# LPC111x_LPC11Cxx register map
File version: 6
CPU: CM0 r0p0, little endian, no MPU, no FPU, 0x2 interrupt priority bits, 0x0 interrupts
Registers are 32-bit, read-write, reset 0x0 unless marked. A register's access mark holds for its fields unless they carry their own. Offsets are from the block's base; [hi:lo] are bit positions; 'fields as' and 'values as' point back to an identical list.

## IOCON — Product name title=UM10398 Chapter title=LPC1100XL series: I/O configuration (IOCONFIG) Modification date=2/22/2012 Major revision=8 Minor revision=not available
Base 0x40044000
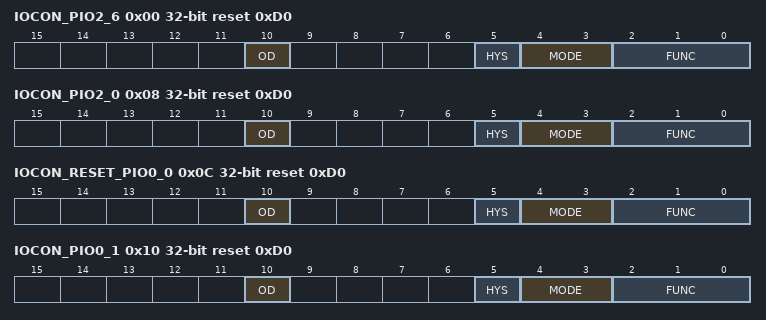
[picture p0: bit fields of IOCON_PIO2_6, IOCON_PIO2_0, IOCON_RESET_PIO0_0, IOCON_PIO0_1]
0x00 IOCON_PIO2_6 reset 0xD0 — I/O configuration for pin PIO2_6/ CT32B0_MAT1
  [10] OD — Selects pseudo open-drain mode.
    0=STANDARD_GPIO_OUTPUT; 1=OPEN_DRAIN_OUTPUT
  [5] HYS — Hysteresis.
    0=DISABLE_; 1=ENABLE_
  [4:3] MODE — Selects function mode (on-chip pull-up/pull-down resistor control).
    0=INACTIVE_NO_PULL_DO (Inactive (no pull-down/pull-up resistor enabled).); 1=PULL_DOWN_RESISTOR_E (Pull-down resistor enabled.); 2=PULL_UP_RESISTOR_ENA (Pull-up resistor enabled.); 3=REPEATER_MODE_
  [2:0] FUNC — Selects pin function. All other values are reserved.
    0=SELECTS_FUNCTION_PIO (Selects function PIO2_6.); 1=SELECTS_FUNCTION_CT3 (Selects function CT32B0_MAT1.)
0x08 IOCON_PIO2_0 reset 0xD0 — I/O configuration for pin PIO2_0/DTR/SSEL1
  [10] OD — Selects pseudo open-drain mode.
    0=STANDARD_GPIO_OUTPUT; 1=OPEN_DRAIN_OUTPUT
  [5] HYS — Hysteresis.
    0=DISABLE_; 1=ENABLE_
  [4:3] MODE — Selects function mode (on-chip pull-up/pull-down resistor control).
    values as IOCON_PIO2_6.MODE
  [2:0] FUNC — Selects pin function. All other values are reserved.
    0=SELECTS_FUNCTION_PIO (Selects function PIO2_0.); 1=SELECT_FUNCTION_DTR_; 2=SELECT_FUNCTION_SSEL (Select function SSEL1.)
0x0C IOCON_RESET_PIO0_0 reset 0xD0 — I/O configuration for pin RESET/PIO0_0
  [10] OD — Selects pseudo open-drain mode.
    0=STANDARD_GPIO_OUTPUT; 1=OPEN_DRAIN_OUTPUT
  [5] HYS — Hysteresis.
    0=DISABLE_; 1=ENABLE_
  [4:3] MODE — Selects function mode (on-chip pull-up/pull-down resistor control).
    values as IOCON_PIO2_6.MODE
  [2:0] FUNC — Selects pin function. All other values are reserved.
    0=SELECTS_FUNCTION_RES (Selects function RESET.); 1=SELECTS_FUNCTION_PIO (Selects function PIO0_0.)
0x10 IOCON_PIO0_1 reset 0xD0 — I/O configuration for pin PIO0_1/CLKOUT/CT32B0_MAT2
  [10] OD — Selects pseudo open-drain mode.
    0=STANDARD_GPIO_OUTPUT; 1=OPEN_DRAIN_OUTPUT
  [5] HYS — Hysteresis.
    0=DISABLE_; 1=ENABLE_
  [4:3] MODE — Selects function mode (on-chip pull-up/pull-down resistor control).
    values as IOCON_PIO2_6.MODE
  [2:0] FUNC — Selects pin function. All other values are reserved.
    0=SELECTS_FUNCTION_PIO (Selects function PIO0_1.); 1=SELECTS_FUNCTION_CLK (Selects function CLKOUT.); 2=SELECTS_FUNCTION_CT3 (Selects function CT32B0_MAT2.)
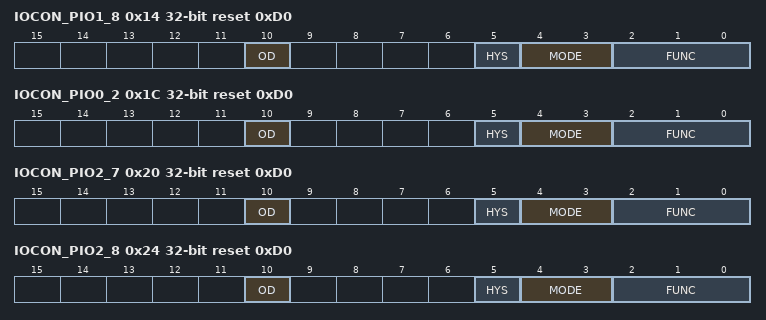
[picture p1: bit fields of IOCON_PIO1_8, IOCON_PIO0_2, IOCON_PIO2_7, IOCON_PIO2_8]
0x14 IOCON_PIO1_8 reset 0xD0 — I/O configuration for pin PIO1_8/CT16B1_CAP0
  [10] OD — Selects pseudo open-drain mode.
    0=STANDARD_GPIO_OUTPUT; 1=OPEN_DRAIN_OUTPUT
  [5] HYS — Hysteresis.
    0=DISABLE_; 1=ENABLE_
  [4:3] MODE — Selects function mode (on-chip pull-up/pull-down resistor control).
    values as IOCON_PIO2_6.MODE
  [2:0] FUNC — Selects pin function. All other values are reserved.
    0=SELECTS_FUNCTION_PIO (Selects function PIO1_8.); 1=SELECTS_FUNCTION_CT1 (Selects function CT16B1_CAP0.)
0x18 IOCON_SSEL1_LOC — SSEL1 pin location select register
  [1:0] SSEL1LOC — Selects pin location for SSEL1 function.
    0=SELECTS_SSEL1_FUNCTI (Selects SSEL1 function in pin location PIO2_2/DCD/MISO1 (see Table 126).); 1=SELECTS_SSEL1_FUNCTI (Selects SSEL1 function in pin location PIO2_4/CT16B1_MAT1/SSEL1 (see Table 119).)
0x1C IOCON_PIO0_2 reset 0xD0 — I/O configuration for pin PIO0_2/SSEL0/CT16B0_CAP0
  [10] OD — Selects pseudo open-drain mode.
    0=STANDARD_GPIO_OUTPUT; 1=OPEN_DRAIN_OUTPUT
  [5] HYS — Hysteresis.
    0=DISABLE_; 1=ENABLE_
  [4:3] MODE — Selects function mode (on-chip pull-up/pull-down resistor control).
    values as IOCON_PIO2_6.MODE
  [2:0] FUNC — Selects pin function. All other values are reserved.
    0=SELECTS_FUNCTION_PIO (Selects function PIO0_2.); 1=SELECTS_FUNCTION_SSE (Selects function SSEL0.); 2=SELECTS_FUNCTION_CT1 (Selects function CT16B0_CAP0.)
0x20 IOCON_PIO2_7 reset 0xD0 — I/O configuration for pin PIO2_7/ CT32B0_MAT2/RXD
  [10] OD — Selects pseudo open-drain mode.
    0=STANDARD_GPIO_OUTPUT; 1=OPEN_DRAIN_OUTPUT
  [5] HYS — Hysteresis.
    0=DISABLE_; 1=ENABLE_
  [4:3] MODE — Selects function mode (on-chip pull-up/pull-down resistor control).
    values as IOCON_PIO2_6.MODE
  [2:0] FUNC — Selects pin function. All other values are reserved.
    0=SELECTS_FUNCTION_PIO (Selects function PIO2_7.); 1=SELECTS_FUNCTION_CT3 (Selects function CT32B0_MAT2.); 2=SELECTS_FUNCTION_RXD
0x24 IOCON_PIO2_8 reset 0xD0 — I/O configuration for pin PIO2_8/ CT32B0_MAT3/TXD
  [10] OD — Selects pseudo open-drain mode.
    0=STANDARD_GPIO_OUTPUT; 1=OPEN_DRAIN_OUTPUT
  [5] HYS — Hysteresis.
    0=DISABLE_; 1=ENABLE_
  [4:3] MODE — Selects function mode (on-chip pull-up/pull-down resistor control).
    values as IOCON_PIO2_6.MODE
  [2:0] FUNC — Selects pin function. All other values are reserved.
    0=SELECTS_FUNCTION_PIO (Selects function PIO2_8.); 1=SELECTS_FUNCTION_CT3 (Selects function CT32B0_MAT3.); 2=SELECTS_FUNCTION_TXD
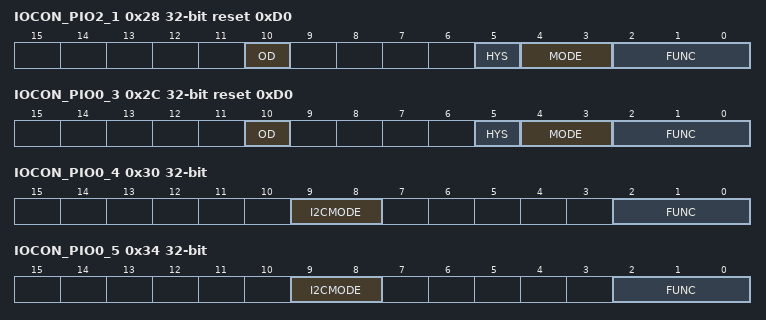
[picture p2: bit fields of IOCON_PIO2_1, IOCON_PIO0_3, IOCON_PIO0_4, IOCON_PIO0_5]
0x28 IOCON_PIO2_1 reset 0xD0 — I/O configuration for pin PIO2_1/DSR/SCK1
  [10] OD — Selects pseudo open-drain mode.
    0=STANDARD_GPIO_OUTPUT; 1=OPEN_DRAIN_OUTPUT
  [5] HYS — Hysteresis.
    0=DISABLE_; 1=ENABLE_
  [4:3] MODE — Selects function mode (on-chip pull-up/pull-down resistor control).
    values as IOCON_PIO2_6.MODE
  [2:0] FUNC — Selects pin function. All other values are reserved.
    0=SELECTS_FUNCTION_PIO (Selects function PIO2_1.); 1=SELECT_FUNCTION_DSR_; 2=SELECT_FUNCTION_SCK1
0x2C IOCON_PIO0_3 reset 0xD0 — I/O configuration for pin PIO0_3
  [10] OD — Selects pseudo open-drain mode.
    0=STANDARD_GPIO_OUTPUT; 1=OPEN_DRAIN_OUTPUT
  [5] HYS — Hysteresis.
    0=DISABLE_; 1=ENABLE_
  [4:3] MODE — Selects function mode (on-chip pull-up/pull-down resistor control).
    values as IOCON_PIO2_6.MODE
  [2:0] FUNC — Selects pin function. All other values are reserved.
    0=SELECTS_FUNCTION_PIO (Selects function PIO0_3.)
0x30 IOCON_PIO0_4 — I/O configuration for pin PIO0_4/SCL
  [9:8] I2CMODE — Selects I2C mode. Select Standard mode (I2CMODE = 00, default) or Standard I/O functionality (I2CMODE = 01) if the pin function is GPIO (FUNC = 000).
    0=STANDARD_MODE_FAST (Standard mode/ Fast-mode I2C.); 1=STANDARD_IO_FUNCTION (Standard I/O functionality); 2=FAST_MODE_PLUS_I2C
  [2:0] FUNC — Selects pin function. All other values are reserved.
    0=SELECTS_FUNCTION_PIO (Selects function PIO0_4 (open-drain pin).); 1=SELECTS_I2C_FUNCTION (Selects I2C function SCL (open-drain pin).)
0x34 IOCON_PIO0_5 — I/O configuration for pin PIO0_5/SDA
  [9:8] I2CMODE — Selects I2C mode. Select Standard mode (I2CMODE = 00, default) or Standard I/O functionality (I2CMODE = 01) if the pin function is GPIO (FUNC = 000).
    values as IOCON_PIO0_4.I2CMODE
  [2:0] FUNC — Selects pin function. All other values are reserved.
    0=SELECTS_FUNCTION_PIO (Selects function PIO0_5 (open-drain pin).); 1=SELECTS_I2C_FUNCTION (Selects I2C function SDA (open-drain pin).)
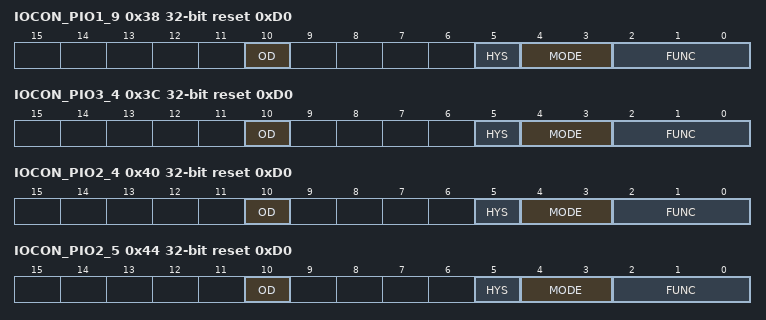
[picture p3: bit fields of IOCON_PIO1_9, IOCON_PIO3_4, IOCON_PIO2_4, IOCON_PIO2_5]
0x38 IOCON_PIO1_9 reset 0xD0 — I/O configuration for pin PIO1_9/CT16B1_MAT0/ MOSI1
  [10] OD — Selects pseudo open-drain mode.
    0=STANDARD_GPIO_OUTPUT; 1=OPEN_DRAIN_OUTPUT
  [5] HYS — Hysteresis.
    0=DISABLE_; 1=ENABLE_
  [4:3] MODE — Selects function mode (on-chip pull-up/pull-down resistor control).
    values as IOCON_PIO2_6.MODE
  [2:0] FUNC — Selects pin function. All other values are reserved.
    0=SELECTS_FUNCTION_PIO (Selects function PIO1_9.); 1=SELECTS_FUNCTION_CT1 (Selects function CT16B1_MAT0.); 2=SELECTS_FUNCTION_MOS (Selects function MOSI1.)
0x3C IOCON_PIO3_4 reset 0xD0 — I/O configuration for pin PIO3_4/ CT16B0_CAP1/RXD
  [10] OD — Selects pseudo open-drain mode.
    0=STANDARD_GPIO_OUTPUT; 1=OPEN_DRAIN_OUTPUT
  [5] HYS — Hysteresis.
    0=DISABLE_; 1=ENABLE_
  [4:3] MODE — Selects function mode (on-chip pull-up/pull-down resistor control).
    values as IOCON_PIO2_6.MODE
  [2:0] FUNC — Selects pin function. All other values are reserved.
    0=SELECTS_FUNCTION_PIO (Selects function PIO3_4.); 1=SELECTS_FUNCTION_CT1 (Selects function CT16B0_CAP1.); 2=SELECTS_FUNCTION_RXD
0x40 IOCON_PIO2_4 reset 0xD0 — I/O configuration for pin PIO2_4/ CT16B1_MAT1/ SSEL1
  [10] OD — Selects pseudo open-drain mode.
    0=STANDARD_GPIO_OUTPUT; 1=OPEN_DRAIN_OUTPUT
  [5] HYS — Hysteresis.
    0=DISABLE_; 1=ENABLE_
  [4:3] MODE — Selects function mode (on-chip pull-up/pull-down resistor control).
    values as IOCON_PIO2_6.MODE
  [2:0] FUNC — Selects pin function. All other values are reserved.
    0=SELECTS_FUNCTION_PIO (Selects function PIO2_4.); 1=SELECTS_FUNCTION_CT1 (Selects function CT16B1_MAT1.); 2=SELECTS_FUNCTION_SSE (Selects function SSEL1.)
0x44 IOCON_PIO2_5 reset 0xD0 — I/O configuration for pin PIO2_5/ CT32B0_MAT0
  [10] OD — Selects pseudo open-drain mode.
    0=STANDARD_GPIO_OUTPUT; 1=OPEN_DRAIN_OUTPUT
  [5] HYS — Hysteresis.
    0=DISABLE_; 1=ENABLE_
  [4:3] MODE — Selects function mode (on-chip pull-up/pull-down resistor control).
    values as IOCON_PIO2_6.MODE
  [2:0] FUNC — Selects pin function. All other values are reserved.
    0=SELECTS_FUNCTION_PIO (Selects function PIO2_5.); 1=SELECTS_FUNCTION_CT3 (Selects function CT32B0_MAT0.)
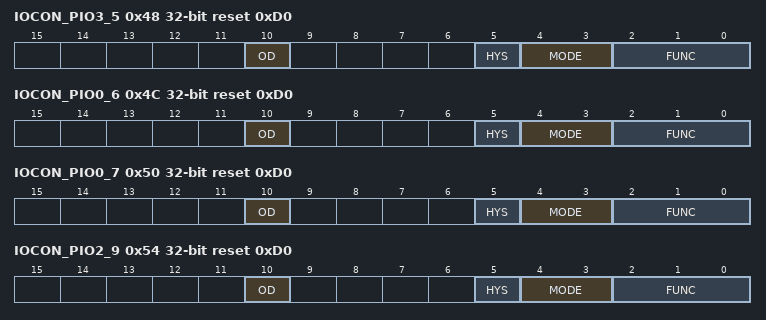
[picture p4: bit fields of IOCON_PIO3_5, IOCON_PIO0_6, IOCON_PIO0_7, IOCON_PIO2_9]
0x48 IOCON_PIO3_5 reset 0xD0 — I/O configuration for pin PIO3_5/ CT16B1_CAP1/TXD
  [10] OD — Selects pseudo open-drain mode.
    0=STANDARD_GPIO_OUTPUT; 1=OPEN_DRAIN_OUTPUT
  [5] HYS — Hysteresis.
    0=DISABLE_; 1=ENABLE_
  [4:3] MODE — Selects function mode (on-chip pull-up/pull-down resistor control).
    values as IOCON_PIO2_6.MODE
  [2:0] FUNC — Selects pin function. All other values are reserved.
    0=SELECTS_FUNCTION_PIO (Selects function PIO3_5.); 1=SELECTS_FUNCTION_CT1 (Selects function CT16B1_CAP1.); 2=SELECTS_FUNCTION_TXD
0x4C IOCON_PIO0_6 reset 0xD0 — I/O configuration for pin PIO0_6/SCK0
  [10] OD — Selects pseudo open-drain mode.
    0=STANDARD_GPIO_OUTPUT; 1=OPEN_DRAIN_OUTPUT
  [5] HYS — Hysteresis.
    0=DISABLE_; 1=ENABLE_
  [4:3] MODE — Selects function mode (on-chip pull-up/pull-down resistor control).
    values as IOCON_PIO2_6.MODE
  [2:0] FUNC — Selects pin function. All other values are reserved.
    0=SELECTS_FUNCTION_PIO (Selects function PIO0_6.); 2=SELECTS_FUNCTION_SCK (Selects function SCK0 (only if pin PIO0_6/SCK0 selected in Table 147).)
0x50 IOCON_PIO0_7 reset 0xD0 — I/O configuration for pin PIO0_7/CTS
  [10] OD — Selects pseudo open-drain mode.
    0=STANDARD_GPIO_OUTPUT; 1=OPEN_DRAIN_OUTPUT
  [5] HYS — Hysteresis.
    0=DISABLE_; 1=ENABLE_
  [4:3] MODE — Selects function mode (on-chip pull-up/pull-down resistor control).
    values as IOCON_PIO2_6.MODE
  [2:0] FUNC — Selects pin function. All other values are reserved.
    0=SELECTS_FUNCTION_PIO (Selects function PIO0_7.); 1=SELECT_FUNCTION_CTS_
0x54 IOCON_PIO2_9 reset 0xD0 — I/O configuration for pin PIO2_9/ CT32B0_CAP0
  [10] OD — Selects pseudo open-drain mode.
    0=STANDARD_GPIO_OUTPUT; 1=OPEN_DRAIN_OUTPUT
  [5] HYS — Hysteresis.
    0=DISABLE_; 1=ENABLE_
  [4:3] MODE — Selects function mode (on-chip pull-up/pull-down resistor control).
    values as IOCON_PIO2_6.MODE
  [2:0] FUNC — Selects pin function. All other values are reserved.
    0=SELECTS_FUNCTION_PIO (Selects function PIO2_9.); 1=SELECTS_FUNCTION_CT3 (Selects function CT32B0_CAP0.)
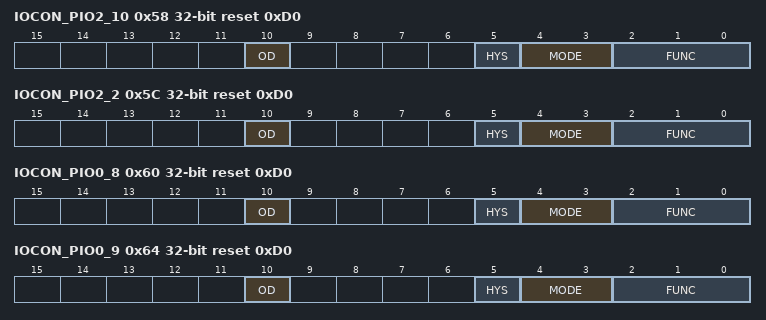
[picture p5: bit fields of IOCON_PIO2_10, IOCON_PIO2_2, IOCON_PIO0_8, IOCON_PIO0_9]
0x58 IOCON_PIO2_10 reset 0xD0 — I/O configuration for pin PIO2_10
  [10] OD — Selects pseudo open-drain mode.
    0=STANDARD_GPIO_OUTPUT; 1=OPEN_DRAIN_OUTPUT
  [5] HYS — Hysteresis.
    0=DISABLE_; 1=ENABLE_
  [4:3] MODE — Selects function mode (on-chip pull-up/pull-down resistor control).
    values as IOCON_PIO2_6.MODE
  [2:0] FUNC — Selects pin function. All other values are reserved.
    0=SELECTS_FUNCTION_PIO (Selects function PIO2_10.)
0x5C IOCON_PIO2_2 reset 0xD0 — I/O configuration for pin PIO2_2/DCD/MISO1
  [10] OD — Selects pseudo open-drain mode.
    0=STANDARD_GPIO_OUTPUT; 1=OPEN_DRAIN_OUTPUT
  [5] HYS — Hysteresis.
    0=DISABLE_; 1=ENABLE_
  [4:3] MODE — Selects function mode (on-chip pull-up/pull-down resistor control).
    values as IOCON_PIO2_6.MODE
  [2:0] FUNC — Selects pin function. All other values are reserved.
    0=SELECTS_FUNCTION_PIO (Selects function PIO2_2.); 1=SELECT_FUNCTION_DCD_; 2=SELECT_FUNCTION_MISO (Select function MISO1.)
0x60 IOCON_PIO0_8 reset 0xD0 — I/O configuration for pin PIO0_8/MISO0/CT16B0_MAT0
  [10] OD — Selects pseudo open-drain mode.
    0=STANDARD_GPIO_OUTPUT; 1=OPEN_DRAIN_OUTPUT
  [5] HYS — Hysteresis.
    0=DISABLE_; 1=ENABLE_
  [4:3] MODE — Selects function mode (on-chip pull-up/pull-down resistor control).
    values as IOCON_PIO2_6.MODE
  [2:0] FUNC — Selects pin function. All other values are reserved.
    0=SELECTS_FUNCTION_PIO (Selects function PIO0_8.); 1=SELECTS_FUNCTION_MIS (Selects function MISO0.); 2=SELECTS_FUNCTION_CT1 (Selects function CT16B0_MAT0.)
0x64 IOCON_PIO0_9 reset 0xD0 — I/O configuration for pin PIO0_9/MOSI0/CT16B0_MAT1
  [10] OD — Selects pseudo open-drain mode.
    0=STANDARD_GPIO_OUTPUT; 1=OPEN_DRAIN_OUTPUT
  [5] HYS — Hysteresis.
    0=DISABLE_; 1=ENABLE_
  [4:3] MODE — Selects function mode (on-chip pull-up/pull-down resistor control).
    values as IOCON_PIO2_6.MODE
  [2:0] FUNC — Selects pin function. All other values are reserved.
    0=SELECTS_FUNCTION_PIO (Selects function PIO0_9.); 1=SELECTS_FUNCTION_MOS (Selects function MOSI0.); 2=SELECTS_FUNCTION_CT1 (Selects function CT16B0_MAT1.)
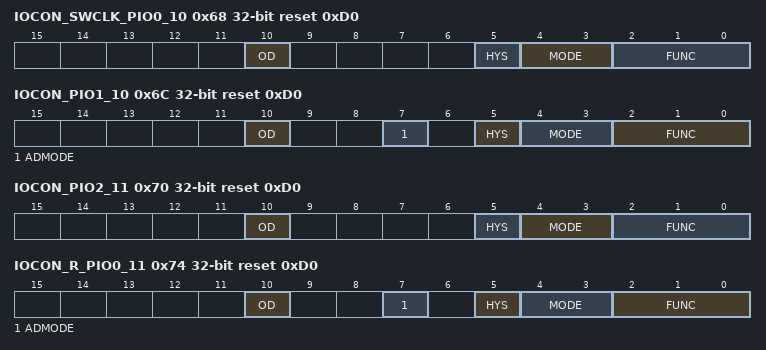
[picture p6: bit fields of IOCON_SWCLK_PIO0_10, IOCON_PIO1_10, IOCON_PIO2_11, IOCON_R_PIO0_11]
0x68 IOCON_SWCLK_PIO0_10 reset 0xD0 — I/O configuration for pin SWCLK/PIO0_10/ SCK0/CT16B0_MAT2
  [10] OD — Selects pseudo open-drain mode.
    0=STANDARD_GPIO_OUTPUT; 1=OPEN_DRAIN_OUTPUT
  [5] HYS — Hysteresis.
    0=DISABLE_; 1=ENABLE_
  [4:3] MODE — Selects function mode (on-chip pull-up/pull-down resistor control).
    values as IOCON_PIO2_6.MODE
  [2:0] FUNC — Selects pin function. All other values are reserved.
    0=SELECTS_FUNCTION_SWC (Selects function SWCLK.); 1=SELECTS_FUNCTION_PIO (Selects function PIO0_10.); 2=SELECTS_FUNCTION_SCK (Selects function SCK0 (only if pin SWCLK/PIO0_10/SCK0/CT16B0_MAT2 selected in Table 147).); 3=SELECTS_FUNCTION_CT1 (Selects function CT16B0_MAT2.)
0x6C IOCON_PIO1_10 reset 0xD0 — I/O configuration for pin PIO1_10/AD6/CT16B1_MAT1/ MISO1
  [10] OD — Selects pseudo open-drain mode.
    0=STANDARD_GPIO_OUTPUT; 1=OPEN_DRAIN_OUTPUT
  [7] ADMODE — Selects Analog/Digital mode
    0=ANALOG_INPUT_MODE; 1=DIGITAL_FUNCTIONAL_M (Digital functional mode)
  [5] HYS — Hysteresis.
    0=DISABLE_; 1=ENABLE_
  [4:3] MODE — Selects function mode (on-chip pull-up/pull-down resistor control).
    values as IOCON_PIO2_6.MODE
  [2:0] FUNC — Selects pin function. All other values are reserved.
    0=SELECTS_FUNCTION_PIO (Selects function PIO1_10.); 1=SELECTS_FUNCTION_AD6; 2=SELECTS_FUNCTION_CT1 (Selects function CT16B1_MAT1.); 3=SELECTS_FUNCTION_MIS (Selects function MISO1.)
0x70 IOCON_PIO2_11 reset 0xD0 — I/O configuration for pin PIO2_11/SCK0/ CT32B0_CAP1
  [10] OD — Selects pseudo open-drain mode.
    0=STANDARD_GPIO_OUTPUT; 1=OPEN_DRAIN_OUTPUT
  [5] HYS — Hysteresis.
    0=DISABLE_; 1=ENABLE_
  [4:3] MODE — Selects function mode (on-chip pull-up/pull-down resistor control).
    values as IOCON_PIO2_6.MODE
  [2:0] FUNC — Selects pin function. All other values are reserved.
    0=SELECTS_FUNCTION_PIO (Selects function PIO2_11.); 1=SELECT_FUNCTION_SCK0 (Select function SCK0 (only if pin PIO2_11/SCK0 selected in Table 147).); 2=SELECT_FUNCTION_CT32 (Select function CT32B0_CAP1.)
0x74 IOCON_R_PIO0_11 reset 0xD0 — I/O configuration for pin R/PIO0_11/AD0/CT32B0_MAT3
  [10] OD — Selects pseudo open-drain mode.
    0=STANDARD_GPIO_OUTPUT; 1=OPEN_DRAIN_OUTPUT
  [7] ADMODE — Selects Analog/Digital mode
    values as IOCON_PIO1_10.ADMODE
  [5] HYS — Hysteresis.
    0=DISABLE_; 1=ENABLE_
  [4:3] MODE — Selects function mode (on-chip pull-up/pull-down resistor control).
    values as IOCON_PIO2_6.MODE
  [2:0] FUNC — Selects pin function. All other values are reserved.
    0=SELECTS_FUNCTION_R_ (Selects function R. This function is reserved. Select one of the alternate functions below.); 1=SELECTS_FUNCTION_PIO (Selects function PIO0_11.); 2=SELECTS_FUNCTION_AD0; 3=SELECTS_FUNCTION_CT3 (Selects function CT32B0_MAT3.)
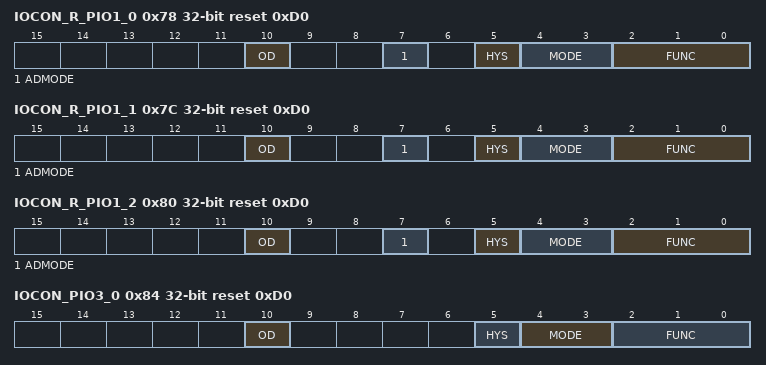
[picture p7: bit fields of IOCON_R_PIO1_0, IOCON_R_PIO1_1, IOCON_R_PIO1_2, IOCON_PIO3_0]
0x78 IOCON_R_PIO1_0 reset 0xD0 — I/O configuration for pin R/PIO1_0/AD1/CT32B1_CAP0
  [10] OD — Selects pseudo open-drain mode.
    0=STANDARD_GPIO_OUTPUT; 1=OPEN_DRAIN_OUTPUT
  [7] ADMODE — Selects Analog/Digital mode
    values as IOCON_PIO1_10.ADMODE
  [5] HYS — Hysteresis.
    0=DISABLE_; 1=ENABLE_
  [4:3] MODE — Selects function mode (on-chip pull-up/pull-down resistor control).
    values as IOCON_PIO2_6.MODE
  [2:0] FUNC — Selects pin function. All other values are reserved.
    0=SELECTS_FUNCTION_R_ (Selects function R. This function is reserved. Select one of the alternate functions below.); 1=SELECTS_FUNCTION_PIO (Selects function PIO1_0.); 2=SELECTS_FUNCTION_AD1; 3=SELECTS_FUNCTION_CT3 (Selects function CT32B1_CAP0.)
0x7C IOCON_R_PIO1_1 reset 0xD0 — I/O configuration for pin R/PIO1_1/AD2/CT32B1_MAT0
  [10] OD — Selects pseudo open-drain mode.
    0=STANDARD_GPIO_OUTPUT; 1=OPEN_DRAIN_OUTPUT
  [7] ADMODE — Selects Analog/Digital mode
    values as IOCON_PIO1_10.ADMODE
  [5] HYS — Hysteresis.
    0=DISABLE_; 1=ENABLE_
  [4:3] MODE — Selects function mode (on-chip pull-up/pull-down resistor control).
    values as IOCON_PIO2_6.MODE
  [2:0] FUNC — Selects pin function. All other values are reserved.
    0=SELECTS_FUNCTION_R_ (Selects function R. This function is reserved. Select one of the alternate functions below.); 1=SELECTS_FUNCTION_PIO (Selects function PIO1_1.); 2=SELECTS_FUNCTION_AD2; 3=SELECTS_FUNCTION_CT3 (Selects function CT32B1_MAT0.)
0x80 IOCON_R_PIO1_2 reset 0xD0 — I/O configuration for pin R/PIO1_2/AD3/CT32B1_MAT1
  [10] OD — Selects pseudo open-drain mode.
    0=STANDARD_GPIO_OUTPUT; 1=OPEN_DRAIN_OUTPUT
  [7] ADMODE — Selects Analog/Digital mode
    values as IOCON_PIO1_10.ADMODE
  [5] HYS — Hysteresis.
    0=DISABLE_; 1=ENABLE_
  [4:3] MODE — Selects function mode (on-chip pull-up/pull-down resistor control).
    values as IOCON_PIO2_6.MODE
  [2:0] FUNC — Selects pin function. All other values are reserved.
    0=SELECTS_FUNCTION_R_ (Selects function R. This function is reserved. Select one of the alternate functions below.); 1=SELECTS_FUNCTION_PIO (Selects function PIO1_2.); 2=SELECTS_FUNCTION_AD3; 3=SELECTS_FUNCTION_CT3 (Selects function CT32B1_MAT1.)
0x84 IOCON_PIO3_0 reset 0xD0 — I/O configuration for pin PIO3_0/DTR/CT16B0_MAT0/TXD
  [10] OD — Selects pseudo open-drain mode.
    0=STANDARD_GPIO_OUTPUT; 1=OPEN_DRAIN_OUTPUT
  [5] HYS — Hysteresis.
    0=DISABLE_; 1=ENABLE_
  [4:3] MODE — Selects function mode (on-chip pull-up/pull-down resistor control).
    values as IOCON_PIO2_6.MODE
  [2:0] FUNC — Selects pin function. All other values are reserved.
    0=SELECTS_FUNCTION_PIO (Selects function PIO3_0.); 1=SELECTS_FUNCTION_DTR; 2=SELECTS_FUNCTION_CT1 (Selects function CT16B0_MAT0.); 3=SELECTS_FUNCTION_TXD
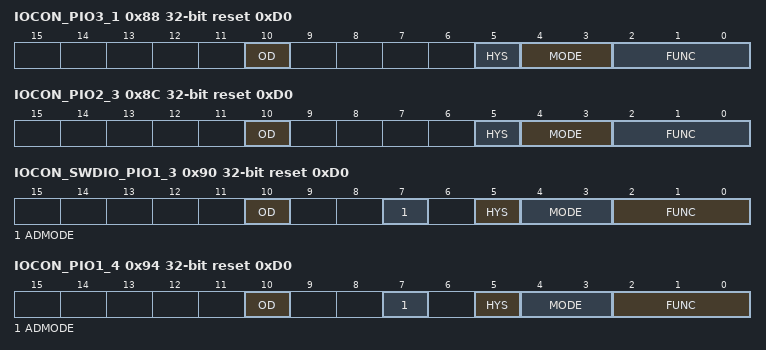
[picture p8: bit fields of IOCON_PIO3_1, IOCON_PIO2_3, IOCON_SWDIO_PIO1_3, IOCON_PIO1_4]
0x88 IOCON_PIO3_1 reset 0xD0 — I/O configuration for pin PIO3_1/DSR/CT16B0_MAT1/RXD
  [10] OD — Selects pseudo open-drain mode.
    0=STANDARD_GPIO_OUTPUT; 1=OPEN_DRAIN_OUTPUT
  [5] HYS — Hysteresis.
    0=DISABLE_; 1=ENABLE_
  [4:3] MODE — Selects function mode (on-chip pull-up/pull-down resistor control).
    values as IOCON_PIO2_6.MODE
  [2:0] FUNC — Selects pin function. All other values are reserved.
    0=SELECTS_FUNCTION_PIO (Selects function PIO3_1.); 1=SELECTS_FUNCTION_DSR; 2=SELECTS_FUNCTION_CT1 (Selects function CT16B0_MAT1.); 3=SELECTS_FUNCTION_RXD
0x8C IOCON_PIO2_3 reset 0xD0 — I/O configuration for pin PIO2_3/RI/MOSI1
  [10] OD — Selects pseudo open-drain mode.
    0=STANDARD_GPIO_OUTPUT; 1=OPEN_DRAIN_OUTPUT
  [5] HYS — Hysteresis.
    0=DISABLE_; 1=ENABLE_
  [4:3] MODE — Selects function mode (on-chip pull-up/pull-down resistor control).
    values as IOCON_PIO2_6.MODE
  [2:0] FUNC — Selects pin function. All other values are reserved.
    0=SELECTS_FUNCTION_PIO (Selects function PIO2_3.); 1=SELECTS_FUNCTION_RI_; 2=SELECTS_FUNCTION_MOS (Selects function MOSI1.)
0x90 IOCON_SWDIO_PIO1_3 reset 0xD0 — I/O configuration for pin SWDIO/PIO1_3/AD4/CT32B1_MAT2
  [10] OD — Selects pseudo open-drain mode.
    0=STANDARD_GPIO_OUTPUT; 1=OPEN_DRAIN_OUTPUT
  [7] ADMODE — Selects Analog/Digital mode
    values as IOCON_PIO1_10.ADMODE
  [5] HYS — Hysteresis.
    0=DISABLE_; 1=ENABLE_
  [4:3] MODE — Selects function mode (on-chip pull-up/pull-down resistor control).
    values as IOCON_PIO2_6.MODE
  [2:0] FUNC — Selects pin function. All other values are reserved.
    0=SELECTS_FUNCTION_SWD (Selects function SWDIO.); 1=SELECTS_FUNCTION_PIO (Selects function PIO1_3.); 2=SELECTS_FUNCTION_AD4; 3=SELECTS_FUNCTION_CT3 (Selects function CT32B1_MAT2.)
0x94 IOCON_PIO1_4 reset 0xD0 — I/O configuration for pin PIO1_4/AD5/CT32B1_MAT3
  [10] OD — Selects pseudo open-drain mode.
    0=STANDARD_GPIO_OUTPUT; 1=OPEN_DRAIN_OUTPUT
  [7] ADMODE — Selects Analog/Digital mode
    values as IOCON_PIO1_10.ADMODE
  [5] HYS — Hysteresis.
    0=DISABLE_; 1=ENABLE_
  [4:3] MODE — Selects function mode (on-chip pull-up/pull-down resistor control).
    values as IOCON_PIO2_6.MODE
  [2:0] FUNC — Selects pin function. This pin functions as WAKEUP pin if the LPC111x/LPC11Cxx is in Deep power-down mode regardless of the value of FUNC. All other values are reserved.
    0=SELECTS_FUNCTION_PIO (Selects function PIO1_4.); 1=SELECTS_FUNCTION_AD5; 2=SELECTS_FUNCTION_CT3 (Selects function CT32B1_MAT3.)
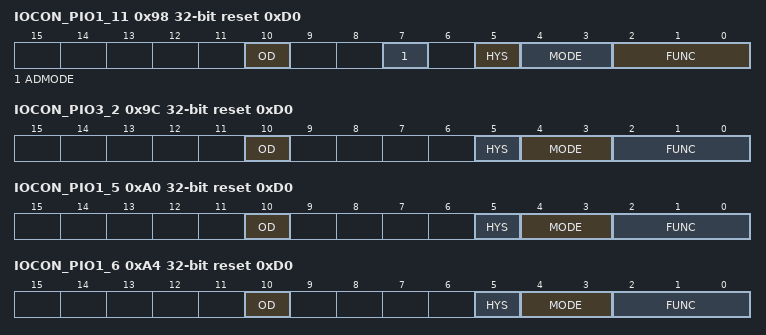
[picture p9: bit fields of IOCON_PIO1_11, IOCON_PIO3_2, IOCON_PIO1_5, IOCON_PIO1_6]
0x98 IOCON_PIO1_11 reset 0xD0 — I/O configuration for pin PIO1_11/AD7/CT32B1_CAP1
  [10] OD — Selects pseudo open-drain mode.
    0=STANDARD_GPIO_OUTPUT; 1=OPEN_DRAIN_OUTPUT
  [7] ADMODE — Selects Analog/Digital mode
    values as IOCON_PIO1_10.ADMODE
  [5] HYS — Hysteresis.
    0=DISABLE_; 1=ENABLE_
  [4:3] MODE — Selects function mode (on-chip pull-up/pull-down resistor control).
    values as IOCON_PIO2_6.MODE
  [2:0] FUNC — Selects pin function. All other values are reserved.
    0=SELECTS_FUNCTION_PIO (Selects function PIO1_11.); 1=SELECTS_FUNCTION_AD7; 2=SELECTS_FUNCTION_CT3 (Selects function CT32B1_CAP1.)
0x9C IOCON_PIO3_2 reset 0xD0 — I/O configuration for pin PIO3_2/DCD/ CT16B0_MAT2/SCK1
  [10] OD — Selects pseudo open-drain mode.
    0=STANDARD_GPIO_OUTPUT; 1=OPEN_DRAIN_OUTPUT
  [5] HYS — Hysteresis.
    0=DISABLE_; 1=ENABLE_
  [4:3] MODE — Selects function mode (on-chip pull-up/pull-down resistor control).
    values as IOCON_PIO2_6.MODE
  [2:0] FUNC — Selects pin function. All other values are reserved.
    0=SELECTS_FUNCTION_PIO (Selects function PIO3_2.); 1=SELECTS_FUNCTION_DCD; 2=SELECTS_FUNCTION_CT1 (Selects function CT16B0_MAT2.); 3=SELECTS_FUNCTION_SCK (Selects function SCK1.)
0xA0 IOCON_PIO1_5 reset 0xD0 — I/O configuration for pin PIO1_5/RTS/CT32B0_CAP0
  [10] OD — Selects pseudo open-drain mode.
    0=STANDARD_GPIO_OUTPUT; 1=OPEN_DRAIN_OUTPUT
  [5] HYS — Hysteresis.
    0=DISABLE_; 1=ENABLE_
  [4:3] MODE — Selects function mode (on-chip pull-up/pull-down resistor control).
    values as IOCON_PIO2_6.MODE
  [2:0] FUNC — Selects pin function. All other values are reserved.
    0=SELECTS_FUNCTION_PIO (Selects function PIO1_5.); 1=SELECTS_FUNCTION_RTS; 2=SELECTS_FUNCTION_CT3 (Selects function CT32B0_CAP0.)
0xA4 IOCON_PIO1_6 reset 0xD0 — I/O configuration for pin PIO1_6/RXD/CT32B0_MAT0
  [10] OD — Selects pseudo open-drain mode.
    0=STANDARD_GPIO_OUTPUT; 1=OPEN_DRAIN_OUTPUT
  [5] HYS — Hysteresis.
    0=DISABLE_; 1=ENABLE_
  [4:3] MODE — Selects function mode (on-chip pull-up/pull-down resistor control).
    values as IOCON_PIO2_6.MODE
  [2:0] FUNC — Selects pin function. All other values are reserved.
    0=SELECTS_FUNCTION_PIO (Selects function PIO1_6.); 1=SELECTS_FUNCTION_RXD; 2=SELECTS_FUNCTION_CT3 (Selects function CT32B0_MAT0.)
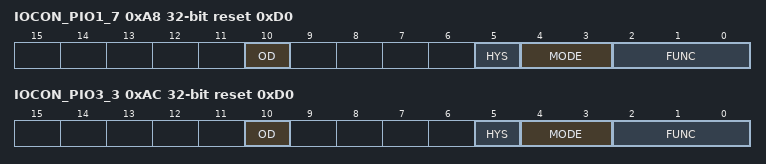
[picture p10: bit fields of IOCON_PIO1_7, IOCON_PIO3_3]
0xA8 IOCON_PIO1_7 reset 0xD0 — I/O configuration for pin PIO1_7/TXD/CT32B0_MAT1
  [10] OD — Selects pseudo open-drain mode.
    0=STANDARD_GPIO_OUTPUT; 1=OPEN_DRAIN_OUTPUT
  [5] HYS — Hysteresis.
    0=DISABLE_; 1=ENABLE_
  [4:3] MODE — Selects function mode (on-chip pull-up/pull-down resistor control).
    values as IOCON_PIO2_6.MODE
  [2:0] FUNC — Selects pin function. All other values are reserved.
    0=SELECTS_FUNCTION_PIO (Selects function PIO1_7.); 1=SELECTS_FUNCTION_TXD; 2=SELECTS_FUNCTION_CT3 (Selects function CT32B0_MAT1.)
0xAC IOCON_PIO3_3 reset 0xD0 — I/O configuration for pin PIO3_3/RI/ CT16B0_CAP0
  [10] OD — Selects pseudo open-drain mode.
    0=STANDARD_GPIO_OUTPUT; 1=OPEN_DRAIN_OUTPUT
  [5] HYS — Hysteresis.
    0=DISABLE_; 1=ENABLE_
  [4:3] MODE — Selects function mode (on-chip pull-up/pull-down resistor control).
    values as IOCON_PIO2_6.MODE
  [2:0] FUNC — Selects pin function. All other values are reserved.
    0=SELECTS_FUNCTION_PIO (Selects function PIO3_3.); 1=SELECTS_FUNCTION_RI_; 2=SELECTS_FUNCTION_CT1 (Selects function CT16B0_CAP0.)
0xB0 IOCON_SCK0_LOC — SCK0 pin location select register
  [1:0] SCKLOC — Selects pin location for SCK0 function.
    0=SELECTS_SCK0_FUNCTIO (Selects SCK0 function in pin location SWCLK/PIO0_10/SCK0/CT16B0_MAT2 (see Table 129).); 1=SELECTS_SCK0_FUNCTIO (Selects SCK0 function in pin location PIO2_11/SCK0 (see Table 131).); 2=SELECTS_SCK0_FUNCTIO (Selects SCK0 function in pin location PIO0_6/SCK0 (see Table 122).)
0xB4 IOCON_DSR_LOC — DSR pin location select register
  [1:0] DSRLOC — Selects pin location for DSR function.
    0=SELECTS_DSR_FUNCTIO (Selects DSR function in pin location PIO2_1/DSR/SCK1 (see Table 113).); 1=SELECTS_DSR_FUNCTION (Selects DSR function in pin location PIO3_1/DSR (see Table 137).)
0xB8 IOCON_DCD_LOC — DCD pin location select register
  [1:0] DCDLOC — Selects pin location for DCD function.
    0=SELECTS_DCD_FUNCTIO (Selects DCD function in pin location PIO2_2/DCD/MISO1 (see Table 126).); 1=SELECTS_DCD_FUNCTION (Selects DCD function in pin location PIO3_2/DCD (see Table 142).)
0xBC IOCON_RI_LOC — RI pin location select register
  [1:0] RILOC — Selects pin location for RI function.
    0=SELECTS_RI_FUNCTION (Selects RI function in pin location PIO2_3/RI/MOSI1 (see Table 138).); 1=SELECTS_RI_FUNCTION_ (Selects RI function in pin location PIO3_3/RI (see Table 146).)
0xC0 IOCON_CT16B0_CAP0_LOC — CT16B0_CAP0 pin location select register
  [1:0] CT16B0_CAP0LOC — Selects pin location for CT16B0_CAP0 function.
    0=SELECTS_CT16B0_CAP0_ (Selects CT16B0_CAP0 function in pin location PIO0_2/SSEL0/CT16B0_CAP0 (see Table 110).); 1=SELECTS_CT16B0_CAP0_ (Selects CT16B0_CAP0 function in pin location PIO3_3/RI/CT16B0 (see Table 146).)
0xC4 IOCON_SCK1_LOC — SCK1 pin location select register
  [1:0] SCK1LOC — Selects pin location for SCK1 function.
    0=SELECTS_SCK1_FUNCTIO (Selects SCK1 function in pin location PIO2_1/DSR/SCK1 (see Table 113).); 1=SELECTS_SCK1_FUNCTIO (Selects SCK1 function in pin location PIO3_2/DCD/CT16B0_MAT2/SCK1 (see Table 142).)
0xC8 IOCON_MISO1_LOC — MISO1 pin location select register
  [1:0] MISO1LOC — Selects pin location for the MISO1 function.
    0=SELECTS_MISO1_FUNCTI (Selects MISO1 function in pin location PIO2_2/DCD/MISO1 (see Table 126).); 1=SELECTS_MISO1_FUNCTI (Selects MISO1 function in pin location PIO1_10/AD6/CT16B1_MAT1/MISO1 (see Table 130).)
0xCC IOCON_MOSI1_LOC — MOSI1 pin location select register
  [1:0] MOSI1LOC — Selects pin location for the MOSI1 function.
    0=SELECTS_MOSI1_FUNCTI (Selects MOSI1 function in pin location PIO2_3/RI/MOSI1 (see Table 138).); 1=SELECTS_MOSI1_FUNCTI (Selects MOSI1 function in pin location PIO1_9/CT16B1_MAT0/MOSI1 (see Table 117).)
0xD0 IOCON_CT32B0_CAP0_LOC — CT32B0_CAP0 pin location select register
  [1:0] CT32B0_CAP0LOC — Selects pin location for the CT32B0_CAP0 function.
    0=SELECTS_CT32B0_CAP0_ (Selects CT32B0_CAP0 function in pin location PIO1_5/RTS/CT32B0_CAP0 (see Table 143).); 1=SELECTS_CT32B0_CAP0_ (Selects CT32B0_CAP0 function in pin location PIO2_9/CT32B0_CAP0 (Table 124).)
0xD4 IOCON_RXD_LOC — RXD pin location select register
  [1:0] RXDLOC — Selects pin location for the RXD function.
    0=SELECTS_RXD_FUNCTION (Selects RXD function in pin location PIO1_6/RXD/CT32B0_MAT0 (see Table 144).); 1=SELECTS_RXD_FUNCTION (Selects RXD function in pin location PIO2_7/CT32B0_MAT2/RXD (see Table 111).); 2=SELECTS_RXD_FUNCTION (Selects RXD function in pin location PIO3_1/DSR/CT16B0_MAT1/RXD (see Table 137).); 3=SELECTS_RXD_FUNCTION (Selects RXD function in pin location PIO3_4/CT16B0_CAP1/RXD (see Table 118).)
